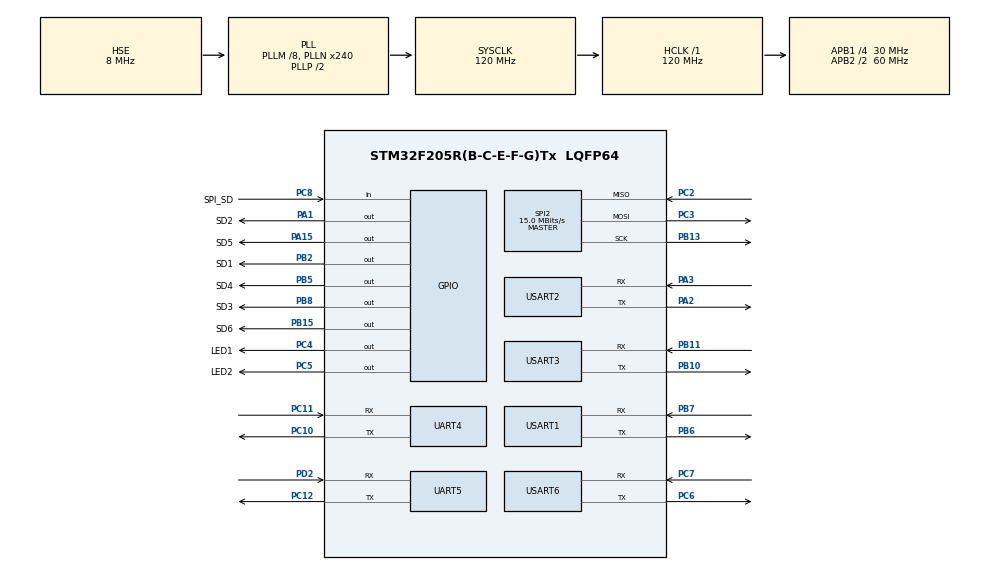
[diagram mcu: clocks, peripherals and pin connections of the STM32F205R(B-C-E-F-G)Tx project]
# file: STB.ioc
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Mcu.Family=STM32F2
Mcu.Name=STM32F205R(B-C-E-F-G)Tx
Mcu.Package=LQFP64
NVIC.PriorityGroup=NVIC_PRIORITYGROUP_4
PA1.GPIO_Label=SD2
PA1.Signal=GPIO_Output
PA13.Mode=Serial_Wire
PA13.Signal=SYS_JTMS-SWDIO
PA14.Mode=Serial_Wire
PA14.Signal=SYS_JTCK-SWCLK
PA15.GPIO_Label=SD5
PA15.Signal=GPIO_Output
PA2.Mode=IrDA
PA2.Signal=USART2_TX
PA3.Mode=IrDA
PA3.Signal=USART2_RX
PB10.Mode=IrDA
PB10.Signal=USART3_TX
PB11.Mode=IrDA
PB11.Signal=USART3_RX
PB13.Mode=Full_Duplex_Master
PB13.Signal=SPI2_SCK
PB15.GPIO_Label=SD6
PB15.Signal=GPIO_Output
PB2.GPIO_Label=SD1
PB2.Signal=GPIO_Output
PB5.GPIO_Label=SD4
PB5.Signal=GPIO_Output
PB6.Mode=IrDA
PB6.Signal=USART1_TX
PB7.Mode=IrDA
PB7.Signal=USART1_RX
PB8.GPIO_Label=SD3
PB8.Signal=GPIO_Output
PC10.Mode=IrDA
PC10.Signal=UART4_TX
PC11.Mode=IrDA
PC11.Signal=UART4_RX
PC12.Mode=IrDA
PC12.Signal=UART5_TX
PC2.Mode=Full_Duplex_Master
PC2.Signal=SPI2_MISO
PC3.Mode=Full_Duplex_Master
PC3.Signal=SPI2_MOSI
PC4.GPIO_Label=LED1
PC4.Signal=GPIO_Output
PC5.GPIO_Label=LED2
PC5.Signal=GPIO_Output
PC6.Mode=IrDA
PC6.Signal=USART6_TX
PC7.Mode=IrDA
PC7.Signal=USART6_RX
PC8.GPIO_Label=SPI_SD
PC8.Signal=GPIO_Input
PD2.Mode=IrDA
PD2.Signal=UART5_RX
PH0-OSC_IN.Mode=HSE-External-Oscillator
PH0-OSC_IN.Signal=RCC_OSC_IN
PH1-OSC_OUT.Mode=HSE-External-Oscillator
PH1-OSC_OUT.Signal=RCC_OSC_OUT
ProjectManager.HeapSize=0x200
ProjectManager.StackSize=0x400
ProjectManager.TargetToolchain=MDK-ARM V5
RCC.48MHZClocksFreq_Value=60000000
RCC.AHBFreq_Value=120000000
RCC.APB1CLKDivider=RCC_HCLK_DIV4
RCC.APB1Freq_Value=30000000
RCC.APB1TimFreq_Value=60000000
RCC.APB2CLKDivider=RCC_HCLK_DIV2
RCC.APB2Freq_Value=60000000
RCC.APB2TimFreq_Value=120000000
RCC.CortexFreq_Value=120000000
RCC.HCLKFreq_Value=120000000
RCC.HSE_VALUE=8000000
RCC.HSI_VALUE=16000000
RCC.LSE_VALUE=32768
RCC.PLLM=8
RCC.PLLN=240
RCC.PLLSourceVirtual=RCC_PLLSOURCE_HSE
RCC.SYSCLKFreq_VALUE=120000000
RCC.SYSCLKSource=RCC_SYSCLKSOURCE_PLLCLK
RCC.VCOOutputFreq_Value=240000000
SPI2.BaudRatePrescaler=SPI_BAUDRATEPRESCALER_2
SPI2.CalculateBaudRate=15.0 MBits/s
SPI2.Direction=SPI_DIRECTION_2LINES
SPI2.Mode=SPI_MODE_MASTER
SPI2.VirtualType=VM_MASTER
UART4.VirtualMode=IrDA
UART5.VirtualMode=IrDA
USART1.VirtualMode=VM_IRDA
USART2.VirtualMode=VM_IRDA
USART3.VirtualMode=VM_IRDA
USART6.VirtualMode=VM_IRDA
board=STB

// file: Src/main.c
/**
  ******************************************************************************
  * @file           : main.c
  * @brief          : Main program body
  ******************************************************************************
  ** This notice applies to any and all portions of this file
  * that are not between comment pairs USER CODE BEGIN and
  * USER CODE END. Other portions of this file, whether
  * inserted by the user or by software development tools
  * are owned by their respective copyright owners.
  *
  * COPYRIGHT(c) 2018 STMicroelectronics
  *
  * Redistribution and use in source and binary forms, with or without modification,
  * are permitted provided that the following conditions are met:
  *   1. Redistributions of source code must retain the above copyright notice,
  *      this list of conditions and the following disclaimer.
  *   2. Redistributions in binary form must reproduce the above copyright notice,
  *      this list of conditions and the following disclaimer in the documentation
  *      and/or other materials provided with the distribution.
  *   3. Neither the name of STMicroelectronics nor the names of its contributors
  *      may be used to endorse or promote products derived from this software
  *      without specific prior written permission.
  *
  * THIS SOFTWARE IS PROVIDED BY THE COPYRIGHT HOLDERS AND CONTRIBUTORS "AS IS"
  * AND ANY EXPRESS OR IMPLIED WARRANTIES, INCLUDING, BUT NOT LIMITED TO, THE
  * IMPLIED WARRANTIES OF MERCHANTABILITY AND FITNESS FOR A PARTICULAR PURPOSE ARE
  * DISCLAIMED. IN NO EVENT SHALL THE COPYRIGHT HOLDER OR CONTRIBUTORS BE LIABLE
  * FOR ANY DIRECT, INDIRECT, INCIDENTAL, SPECIAL, EXEMPLARY, OR CONSEQUENTIAL
  * DAMAGES (INCLUDING, BUT NOT LIMITED TO, PROCUREMENT OF SUBSTITUTE GOODS OR
  * SERVICES; LOSS OF USE, DATA, OR PROFITS; OR BUSINESS INTERRUPTION) HOWEVER
  * CAUSED AND ON ANY THEORY OF LIABILITY, WHETHER IN CONTRACT, STRICT LIABILITY,
  * OR TORT (INCLUDING NEGLIGENCE OR OTHERWISE) ARISING IN ANY WAY OUT OF THE USE
  * OF THIS SOFTWARE, EVEN IF ADVISED OF THE POSSIBILITY OF SUCH DAMAGE.
  *
  ******************************************************************************
  */
#include "main.h"
#include "stm32f2xx_hal.h"

SPI_HandleTypeDef hspi2;

IRDA_HandleTypeDef hirda4;
IRDA_HandleTypeDef hirda5;
IRDA_HandleTypeDef hirda1;
IRDA_HandleTypeDef hirda2;
IRDA_HandleTypeDef hirda3;
IRDA_HandleTypeDef hirda6;

/* USER CODE BEGIN PV */
/* Private variables ---------------------------------------------------------*/

/* USER CODE END PV */

void SystemClock_Config(void);
static void MX_GPIO_Init(void);
static void MX_UART4_IRDA_Init(void);
static void MX_UART5_IRDA_Init(void);
static void MX_USART1_IRDA_Init(void);
static void MX_USART2_IRDA_Init(void);
static void MX_USART3_IRDA_Init(void);
static void MX_USART6_IRDA_Init(void);
static void MX_SPI2_Init(void);

/* USER CODE BEGIN PFP */
/* Private function prototypes -----------------------------------------------*/

/* USER CODE END PFP */

int main(void)
{

  /* MCU Configuration----------------------------------------------------------*/

  /* Reset of all peripherals, Initializes the Flash interface and the Systick. */
  HAL_Init();

  /* Configure the system clock */
  SystemClock_Config();

  /* Initialize all configured peripherals */
  MX_GPIO_Init();
  MX_UART4_IRDA_Init();
  MX_UART5_IRDA_Init();
  MX_USART1_IRDA_Init();
  MX_USART2_IRDA_Init();
  MX_USART3_IRDA_Init();
  MX_USART6_IRDA_Init();
  MX_SPI2_Init();

  /* Infinite loop */
  /* USER CODE BEGIN WHILE */
  while (1)
  {
	  HAL_GPIO_TogglePin(LED1_GPIO_Port, LED1_Pin);
	  HAL_Delay(100);

  /* USER CODE END WHILE */

  }

}

void SystemClock_Config(void)
{

  RCC_OscInitTypeDef RCC_OscInitStruct;
  RCC_ClkInitTypeDef RCC_ClkInitStruct;

    /**Initializes the CPU, AHB and APB busses clocks
    */
  RCC_OscInitStruct.OscillatorType = RCC_OSCILLATORTYPE_HSE;
  RCC_OscInitStruct.HSEState = RCC_HSE_ON;
  RCC_OscInitStruct.PLL.PLLState = RCC_PLL_ON;
  RCC_OscInitStruct.PLL.PLLSource = RCC_PLLSOURCE_HSE;
  RCC_OscInitStruct.PLL.PLLM = 8;
  RCC_OscInitStruct.PLL.PLLN = 240;
  RCC_OscInitStruct.PLL.PLLP = RCC_PLLP_DIV2;
  RCC_OscInitStruct.PLL.PLLQ = 4;
  if (HAL_RCC_OscConfig(&RCC_OscInitStruct) != HAL_OK)
  {
    _Error_Handler(__FILE__, __LINE__);
  }

    /**Initializes the CPU, AHB and APB busses clocks
    */
  RCC_ClkInitStruct.ClockType = RCC_CLOCKTYPE_HCLK|RCC_CLOCKTYPE_SYSCLK
                              |RCC_CLOCKTYPE_PCLK1|RCC_CLOCKTYPE_PCLK2;
  RCC_ClkInitStruct.SYSCLKSource = RCC_SYSCLKSOURCE_PLLCLK;
  RCC_ClkInitStruct.AHBCLKDivider = RCC_SYSCLK_DIV1;
  RCC_ClkInitStruct.APB1CLKDivider = RCC_HCLK_DIV4;
  RCC_ClkInitStruct.APB2CLKDivider = RCC_HCLK_DIV2;

  if (HAL_RCC_ClockConfig(&RCC_ClkInitStruct, FLASH_LATENCY_3) != HAL_OK)
  {
    _Error_Handler(__FILE__, __LINE__);
  }

    /**Configure the Systick interrupt time
    */
  HAL_SYSTICK_Config(HAL_RCC_GetHCLKFreq()/1000);

    /**Configure the Systick
    */
  HAL_SYSTICK_CLKSourceConfig(SYSTICK_CLKSOURCE_HCLK);

  /* SysTick_IRQn interrupt configuration */
  HAL_NVIC_SetPriority(SysTick_IRQn, 0, 0);
}

/* SPI2 init function */
static void MX_SPI2_Init(void)
{

  /* SPI2 parameter configuration*/
  hspi2.Instance = SPI2;
  hspi2.Init.Mode = SPI_MODE_MASTER;
  hspi2.Init.Direction = SPI_DIRECTION_2LINES;
  hspi2.Init.DataSize = SPI_DATASIZE_8BIT;
  hspi2.Init.CLKPolarity = SPI_POLARITY_LOW;
  hspi2.Init.CLKPhase = SPI_PHASE_1EDGE;
  hspi2.Init.NSS = SPI_NSS_SOFT;
  hspi2.Init.BaudRatePrescaler = SPI_BAUDRATEPRESCALER_2;
  hspi2.Init.FirstBit = SPI_FIRSTBIT_MSB;
  hspi2.Init.TIMode = SPI_TIMODE_DISABLE;
  hspi2.Init.CRCCalculation = SPI_CRCCALCULATION_DISABLE;
  hspi2.Init.CRCPolynomial = 10;
  if (HAL_SPI_Init(&hspi2) != HAL_OK)
  {
    _Error_Handler(__FILE__, __LINE__);
  }

}

/* UART4 init function */
static void MX_UART4_IRDA_Init(void)
{

  hirda4.Instance = UART4;
  hirda4.Init.BaudRate = 115200;
  hirda4.Init.WordLength = IRDA_WORDLENGTH_8B;
  hirda4.Init.Parity = IRDA_PARITY_NONE;
  hirda4.Init.Mode = IRDA_MODE_TX_RX;
  hirda4.Init.Prescaler = 1;
  hirda4.Init.IrDAMode = IRDA_POWERMODE_NORMAL;
  if (HAL_IRDA_Init(&hirda4) != HAL_OK)
  {
    _Error_Handler(__FILE__, __LINE__);
  }

}

/* UART5 init function */
static void MX_UART5_IRDA_Init(void)
{

  hirda5.Instance = UART5;
  hirda5.Init.BaudRate = 115200;
  hirda5.Init.WordLength = IRDA_WORDLENGTH_8B;
  hirda5.Init.Parity = IRDA_PARITY_NONE;
  hirda5.Init.Mode = IRDA_MODE_TX_RX;
  hirda5.Init.Prescaler = 1;
  hirda5.Init.IrDAMode = IRDA_POWERMODE_NORMAL;
  if (HAL_IRDA_Init(&hirda5) != HAL_OK)
  {
    _Error_Handler(__FILE__, __LINE__);
  }

}

/* USART1 init function */
static void MX_USART1_IRDA_Init(void)
{

  hirda1.Instance = USART1;
  hirda1.Init.BaudRate = 115200;
  hirda1.Init.WordLength = IRDA_WORDLENGTH_8B;
  hirda1.Init.Parity = IRDA_PARITY_NONE;
  hirda1.Init.Mode = IRDA_MODE_TX_RX;
  hirda1.Init.Prescaler = 1;
  hirda1.Init.IrDAMode = IRDA_POWERMODE_NORMAL;
  if (HAL_IRDA_Init(&hirda1) != HAL_OK)
  {
    _Error_Handler(__FILE__, __LINE__);
  }

}

/* USART2 init function */
static void MX_USART2_IRDA_Init(void)
{

  hirda2.Instance = USART2;
  hirda2.Init.BaudRate = 115200;
  hirda2.Init.WordLength = IRDA_WORDLENGTH_8B;
  hirda2.Init.Parity = IRDA_PARITY_NONE;
  hirda2.Init.Mode = IRDA_MODE_TX_RX;
  hirda2.Init.Prescaler = 1;
  hirda2.Init.IrDAMode = IRDA_POWERMODE_NORMAL;
  if (HAL_IRDA_Init(&hirda2) != HAL_OK)
  {
    _Error_Handler(__FILE__, __LINE__);
  }

}

/* USART3 init function */
static void MX_USART3_IRDA_Init(void)
{

  hirda3.Instance = USART3;
  hirda3.Init.BaudRate = 115200;
  hirda3.Init.WordLength = IRDA_WORDLENGTH_8B;
  hirda3.Init.Parity = IRDA_PARITY_NONE;
  hirda3.Init.Mode = IRDA_MODE_TX_RX;
  hirda3.Init.Prescaler = 1;
  hirda3.Init.IrDAMode = IRDA_POWERMODE_NORMAL;
  if (HAL_IRDA_Init(&hirda3) != HAL_OK)
  {
    _Error_Handler(__FILE__, __LINE__);
  }

}

/* USART6 init function */
static void MX_USART6_IRDA_Init(void)
{

  hirda6.Instance = USART6;
  hirda6.Init.BaudRate = 115200;
  hirda6.Init.WordLength = IRDA_WORDLENGTH_8B;
  hirda6.Init.Parity = IRDA_PARITY_NONE;
  hirda6.Init.Mode = IRDA_MODE_TX_RX;
  hirda6.Init.Prescaler = 1;
  hirda6.Init.IrDAMode = IRDA_POWERMODE_NORMAL;
  if (HAL_IRDA_Init(&hirda6) != HAL_OK)
  {
    _Error_Handler(__FILE__, __LINE__);
  }

}

/** Configure pins as
        * Analog
        * Input
        * Output
        * EVENT_OUT
        * EXTI
*/
static void MX_GPIO_Init(void)
{

  GPIO_InitTypeDef GPIO_InitStruct;

  /* GPIO Ports Clock Enable */
  __HAL_RCC_GPIOH_CLK_ENABLE();
  __HAL_RCC_GPIOC_CLK_ENABLE();
  __HAL_RCC_GPIOA_CLK_ENABLE();
  __HAL_RCC_GPIOB_CLK_ENABLE();
  __HAL_RCC_GPIOD_CLK_ENABLE();

  /*Configure GPIO pin Output Level */
  HAL_GPIO_WritePin(GPIOA, SD2_Pin|SD5_Pin, GPIO_PIN_RESET);

  /*Configure GPIO pin Output Level */
  HAL_GPIO_WritePin(GPIOC, LED1_Pin|LED2_Pin, GPIO_PIN_SET);

  /*Configure GPIO pin Output Level */
  HAL_GPIO_WritePin(GPIOB, SD1_Pin|SD6_Pin|SD4_Pin|SD3_Pin, GPIO_PIN_RESET);

  /*Configure GPIO pins : SD2_Pin SD5_Pin */
  GPIO_InitStruct.Pin = SD2_Pin|SD5_Pin;
  GPIO_InitStruct.Mode = GPIO_MODE_OUTPUT_PP;
  GPIO_InitStruct.Pull = GPIO_NOPULL;
  GPIO_InitStruct.Speed = GPIO_SPEED_FREQ_LOW;
  HAL_GPIO_Init(GPIOA, &GPIO_InitStruct);

  /*Configure GPIO pins : LED1_Pin LED2_Pin */
  GPIO_InitStruct.Pin = LED1_Pin|LED2_Pin;
  GPIO_InitStruct.Mode = GPIO_MODE_OUTPUT_PP;
  GPIO_InitStruct.Pull = GPIO_NOPULL;
  GPIO_InitStruct.Speed = GPIO_SPEED_FREQ_LOW;
  HAL_GPIO_Init(GPIOC, &GPIO_InitStruct);

  /*Configure GPIO pins : SD1_Pin SD6_Pin SD4_Pin SD3_Pin */
  GPIO_InitStruct.Pin = SD1_Pin|SD6_Pin|SD4_Pin|SD3_Pin;
  GPIO_InitStruct.Mode = GPIO_MODE_OUTPUT_PP;
  GPIO_InitStruct.Pull = GPIO_NOPULL;
  GPIO_InitStruct.Speed = GPIO_SPEED_FREQ_LOW;
  HAL_GPIO_Init(GPIOB, &GPIO_InitStruct);

  /*Configure GPIO pin : SPI_SD_Pin */
  GPIO_InitStruct.Pin = SPI_SD_Pin;
  GPIO_InitStruct.Mode = GPIO_MODE_INPUT;
  GPIO_InitStruct.Pull = GPIO_NOPULL;
  HAL_GPIO_Init(SPI_SD_GPIO_Port, &GPIO_InitStruct);

}

void _Error_Handler(char *file, int line)
{
  while(1)
  {
  }
}

/************************ (C) COPYRIGHT STMicroelectronics *****END OF FILE****/
